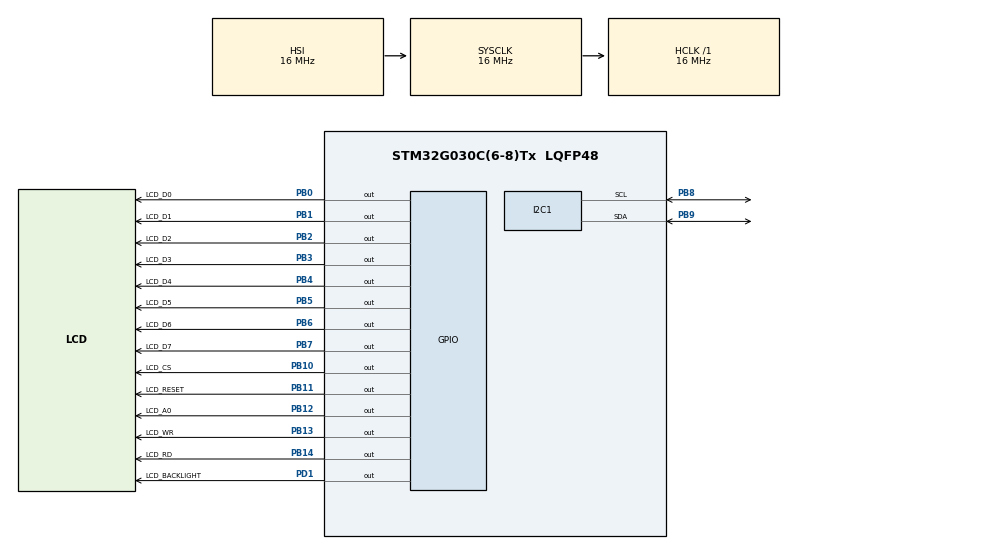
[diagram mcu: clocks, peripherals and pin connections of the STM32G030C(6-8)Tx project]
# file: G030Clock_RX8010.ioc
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I2C1.Timing=0x00503D58
Mcu.Family=STM32G0
Mcu.Name=STM32G030C(6-8)Tx
Mcu.Package=LQFP48
PA13.Mode=Serial_Wire
PA13.Signal=SYS_SWDIO
PA14-BOOT0.Mode=Serial_Wire
PA14-BOOT0.Signal=SYS_SWCLK
PB0.GPIO_Label=LCD_D0
PB0.Signal=GPIO_Output
PB1.GPIO_Label=LCD_D1
PB1.Signal=GPIO_Output
PB10.GPIO_Label=LCD_CS
PB10.Signal=GPIO_Output
PB11.GPIO_Label=LCD_RESET
PB11.Signal=GPIO_Output
PB12.GPIO_Label=LCD_A0
PB12.Signal=GPIO_Output
PB13.GPIO_Label=LCD_WR
PB13.Signal=GPIO_Output
PB14.GPIO_Label=LCD_RD
PB14.Signal=GPIO_Output
PB2.GPIO_Label=LCD_D2
PB2.Signal=GPIO_Output
PB3.GPIO_Label=LCD_D3
PB3.Signal=GPIO_Output
PB4.GPIO_Label=LCD_D4
PB4.Signal=GPIO_Output
PB5.GPIO_Label=LCD_D5
PB5.Signal=GPIO_Output
PB6.GPIO_Label=LCD_D6
PB6.Signal=GPIO_Output
PB7.GPIO_Label=LCD_D7
PB7.Signal=GPIO_Output
PB8.Mode=I2C
PB8.Signal=I2C1_SCL
PB9.Mode=I2C
PB9.Signal=I2C1_SDA
PD1.GPIO_Label=LCD_BACKLIGHT
PD1.Signal=GPIO_Output
PF0-OSC_IN\ (PF0).Mode=HSE-External-Oscillator
PF0-OSC_IN\ (PF0).Signal=RCC_OSC_IN
PF1-OSC_OUT\ (PF1).Mode=HSE-External-Oscillator
PF1-OSC_OUT\ (PF1).Signal=RCC_OSC_OUT
ProjectManager.HeapSize=0x200
ProjectManager.StackSize=0x400
ProjectManager.TargetToolchain=STM32CubeIDE
RCC.AHBFreq_Value=16000000
RCC.CortexFreq_Value=16000000
RCC.EXTERNAL_CLOCK_VALUE=12288000
RCC.HCLKFreq_Value=16000000
RCC.HSE_VALUE=8000000
RCC.HSI_VALUE=16000000
RCC.LSE_VALUE=32768
RCC.SYSCLKFreq_VALUE=16000000
RCC.VCOOutputFreq_Value=128000000
board=custom

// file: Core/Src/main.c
/* USER CODE BEGIN Header */
/**
  ******************************************************************************
  * @file           : main.c
  * @brief          : Main program body
  ******************************************************************************
  * @attention
  *
  * Copyright (c) 2026 STMicroelectronics.
  * All rights reserved.
  *
  * This software is licensed under terms that can be found in the LICENSE file
  * in the root directory of this software component.
  * If no LICENSE file comes with this software, it is provided AS-IS.
  *
  ******************************************************************************
  */
/* USER CODE END Header */
#include "main.h"
#include "i2c.h"
#include "gpio.h"

/* USER CODE BEGIN Includes */
#include "SPLC501.h"
#include "stdio.h"
#include "RX8010.h"
/* USER CODE END Includes */

void SystemClock_Config(void);

/* USER CODE BEGIN 0 */

RTC_TimeTypeDef rtc;
char clock_display[20];
char date_display[20];

/* USER CODE END 0 */

int main(void)
{

  /* MCU Configuration--------------------------------------------------------*/

  /* Reset of all peripherals, Initializes the Flash interface and the Systick. */
  HAL_Init();

  /* Configure the system clock */
  SystemClock_Config();

  /* Initialize all configured peripherals */
  MX_GPIO_Init();
  MX_I2C1_Init();
  /* USER CODE BEGIN 2 */
  HAL_GPIO_WritePin(LCD_BACKLIGHT_GPIO_Port,LCD_BACKLIGHT_Pin, GPIO_PIN_SET);
  lcd_init();
  HAL_Delay(5);
  lcd_cls();

  RX8010_Init(&rtc , hi2c1);
  RX8010_SetTime(1,56,0,7,7,26 , &rtc);
  /* USER CODE END 2 */

  /* Infinite loop */
  while (1)
  {

    /* USER CODE BEGIN 3 */
    RX8010_GetTime(&rtc);
	sprintf(clock_display , "%02d:%02d:%02d" , rtc.hour , rtc.min , rtc.sec);
	sprintf(date_display , "%02d/%02d/20%02d" , rtc.day , rtc.month , rtc.year);
	LCD_write_string_Medium(15,1,clock_display,0);
	LCD_write_string_Medium(5,20,date_display,0);
	HAL_Delay(1000);
  }
}

void SystemClock_Config(void)
{
  RCC_OscInitTypeDef RCC_OscInitStruct = {0};
  RCC_ClkInitTypeDef RCC_ClkInitStruct = {0};

  /** Configure the main internal regulator output voltage
  */
  HAL_PWREx_ControlVoltageScaling(PWR_REGULATOR_VOLTAGE_SCALE1);

  /** Initializes the RCC Oscillators according to the specified parameters
  * in the RCC_OscInitTypeDef structure.
  */
  RCC_OscInitStruct.OscillatorType = RCC_OSCILLATORTYPE_HSI;
  RCC_OscInitStruct.HSIState = RCC_HSI_ON;
  RCC_OscInitStruct.HSIDiv = RCC_HSI_DIV1;
  RCC_OscInitStruct.HSICalibrationValue = RCC_HSICALIBRATION_DEFAULT;
  RCC_OscInitStruct.PLL.PLLState = RCC_PLL_NONE;
  if (HAL_RCC_OscConfig(&RCC_OscInitStruct) != HAL_OK)
  {
    Error_Handler();
  }

  /** Initializes the CPU, AHB and APB buses clocks
  */
  RCC_ClkInitStruct.ClockType = RCC_CLOCKTYPE_HCLK|RCC_CLOCKTYPE_SYSCLK
                              |RCC_CLOCKTYPE_PCLK1;
  RCC_ClkInitStruct.SYSCLKSource = RCC_SYSCLKSOURCE_HSI;
  RCC_ClkInitStruct.AHBCLKDivider = RCC_SYSCLK_DIV1;
  RCC_ClkInitStruct.APB1CLKDivider = RCC_HCLK_DIV1;

  if (HAL_RCC_ClockConfig(&RCC_ClkInitStruct, FLASH_LATENCY_0) != HAL_OK)
  {
    Error_Handler();
  }
}

void Error_Handler(void)
{
  __disable_irq();
  while (1)
  {
  }
}
